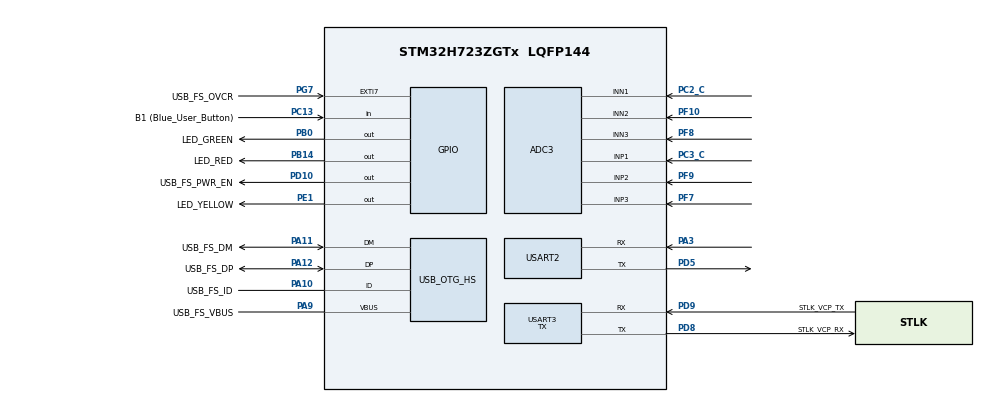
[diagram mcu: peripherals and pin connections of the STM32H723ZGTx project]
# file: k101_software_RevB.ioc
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ADC3.Channel-0\#ChannelRegularConversion=ADC_CHANNEL_1
ADC3.Channel-1\#ChannelRegularConversion=ADC_CHANNEL_2
ADC3.Channel-2\#ChannelRegularConversion=ADC_CHANNEL_3
ADC3.ClockPrescalerADC3=ADC_CLOCK_ASYNC_DIV4
ADC3.ContinuousConvMode=ENABLE
ADC3.ConversionDataManagement=ADC_CONVERSIONDATA_DMA_CIRCULAR
ADC3.DMAContinuousRequests=ENABLE
ADC3.NbrOfConversion=3
ADC3.NbrOfConversionFlag=1
ADC3.OffsetNumber-0\#ChannelRegularConversion=ADC_OFFSET_NONE
ADC3.OffsetNumber-1\#ChannelRegularConversion=ADC_OFFSET_NONE
ADC3.OffsetNumber-2\#ChannelRegularConversion=ADC_OFFSET_NONE
ADC3.OffsetSign-0\#ChannelRegularConversion=ADC3_OFFSET_SIGN_NEGATIVE
ADC3.OffsetSign-1\#ChannelRegularConversion=ADC3_OFFSET_SIGN_NEGATIVE
ADC3.OffsetSign-2\#ChannelRegularConversion=ADC3_OFFSET_SIGN_NEGATIVE
ADC3.Rank-0\#ChannelRegularConversion=1
ADC3.Rank-1\#ChannelRegularConversion=2
ADC3.Rank-2\#ChannelRegularConversion=3
ADC3.SamplingTime-0\#ChannelRegularConversion=ADC3_SAMPLETIME_12CYCLES_5
ADC3.SamplingTime-1\#ChannelRegularConversion=ADC3_SAMPLETIME_12CYCLES_5
ADC3.SamplingTime-2\#ChannelRegularConversion=ADC3_SAMPLETIME_12CYCLES_5
ADC3.SingleDiff-0\#ChannelRegularConversion=ADC_DIFFERENTIAL_ENDED
ADC3.SingleDiff-1\#ChannelRegularConversion=ADC_DIFFERENTIAL_ENDED
ADC3.SingleDiff-2\#ChannelRegularConversion=ADC_DIFFERENTIAL_ENDED
Dma.ADC3.0.Direction=DMA_PERIPH_TO_MEMORY
Dma.ADC3.0.EventEnable=DISABLE
Dma.ADC3.0.FIFOMode=DMA_FIFOMODE_DISABLE
Dma.ADC3.0.Instance=DMA1_Stream1
Dma.ADC3.0.MemDataAlignment=DMA_MDATAALIGN_HALFWORD
Dma.ADC3.0.MemInc=DMA_MINC_ENABLE
Dma.ADC3.0.Mode=DMA_CIRCULAR
Dma.ADC3.0.PeriphDataAlignment=DMA_PDATAALIGN_HALFWORD
Dma.ADC3.0.PeriphInc=DMA_PINC_DISABLE
Dma.ADC3.0.Polarity=HAL_DMAMUX_REQ_GEN_RISING
Dma.ADC3.0.Priority=DMA_PRIORITY_LOW
Dma.ADC3.0.RequestNumber=1
Dma.ADC3.0.SignalID=NONE
Dma.ADC3.0.SyncEnable=DISABLE
Dma.ADC3.0.SyncPolarity=HAL_DMAMUX_SYNC_NO_EVENT
Dma.ADC3.0.SyncRequestNumber=1
Dma.ADC3.0.SyncSignalID=NONE
Dma.Request0=ADC3
Dma.Request1=USART3_TX
Dma.Request2=USART2_TX
Dma.USART2_TX.2.Direction=DMA_MEMORY_TO_PERIPH
Dma.USART2_TX.2.EventEnable=DISABLE
Dma.USART2_TX.2.FIFOMode=DMA_FIFOMODE_DISABLE
Dma.USART2_TX.2.Instance=DMA1_Stream2
Dma.USART2_TX.2.MemDataAlignment=DMA_MDATAALIGN_BYTE
Dma.USART2_TX.2.MemInc=DMA_MINC_ENABLE
Dma.USART2_TX.2.Mode=DMA_NORMAL
Dma.USART2_TX.2.PeriphDataAlignment=DMA_PDATAALIGN_BYTE
Dma.USART2_TX.2.PeriphInc=DMA_PINC_DISABLE
Dma.USART2_TX.2.Polarity=HAL_DMAMUX_REQ_GEN_RISING
Dma.USART2_TX.2.Priority=DMA_PRIORITY_LOW
Dma.USART2_TX.2.RequestNumber=1
Dma.USART2_TX.2.SignalID=NONE
Dma.USART2_TX.2.SyncEnable=DISABLE
Dma.USART2_TX.2.SyncPolarity=HAL_DMAMUX_SYNC_NO_EVENT
Dma.USART2_TX.2.SyncRequestNumber=1
Dma.USART2_TX.2.SyncSignalID=NONE
Dma.USART3_TX.1.Direction=DMA_MEMORY_TO_PERIPH
Dma.USART3_TX.1.EventEnable=DISABLE
Dma.USART3_TX.1.FIFOMode=DMA_FIFOMODE_DISABLE
Dma.USART3_TX.1.Instance=DMA1_Stream0
Dma.USART3_TX.1.MemDataAlignment=DMA_MDATAALIGN_BYTE
Dma.USART3_TX.1.MemInc=DMA_MINC_ENABLE
Dma.USART3_TX.1.Mode=DMA_CIRCULAR
Dma.USART3_TX.1.PeriphDataAlignment=DMA_PDATAALIGN_BYTE
Dma.USART3_TX.1.PeriphInc=DMA_PINC_DISABLE
Dma.USART3_TX.1.Polarity=HAL_DMAMUX_REQ_GEN_RISING
Dma.USART3_TX.1.Priority=DMA_PRIORITY_LOW
Dma.USART3_TX.1.RequestNumber=1
Dma.USART3_TX.1.SignalID=NONE
Dma.USART3_TX.1.SyncEnable=DISABLE
Dma.USART3_TX.1.SyncPolarity=HAL_DMAMUX_SYNC_NO_EVENT
Dma.USART3_TX.1.SyncRequestNumber=1
Dma.USART3_TX.1.SyncSignalID=NONE
Mcu.Family=STM32H7
Mcu.Name=STM32H723ZGTx
Mcu.Package=LQFP144
NVIC.DMA1_Stream0_IRQn=true\:0\:0\:false\:false\:true\:false\:true\:true
NVIC.DMA1_Stream1_IRQn=true\:0\:0\:false\:false\:true\:false\:true\:true
NVIC.DMA1_Stream2_IRQn=true\:0\:0\:false\:false\:true\:false\:true\:true
NVIC.PriorityGroup=NVIC_PRIORITYGROUP_4
PA1.GPIO_Label=RMII_REF_CLK
PA1.Signal=ETH_REF_CLK
PA10.GPIO_Label=USB_FS_ID
PA10.Mode=OTG/Dual-Role-Device-FS
PA10.Signal=USB_OTG_HS_ID
PA11.GPIO_Label=USB_FS_DM
PA11.Mode=OTG/Dual-Role-Device-FS
PA11.Signal=USB_OTG_HS_DM
PA12.GPIO_Label=USB_FS_DP
PA12.Mode=OTG/Dual-Role-Device-FS
PA12.Signal=USB_OTG_HS_DP
PA13(JTMS/SWDIO).GPIO_Label=SWDIO
PA13(JTMS/SWDIO).Mode=Trace_Asynchronous_SW
PA13(JTMS/SWDIO).Signal=DEBUG_JTMS-SWDIO
PA14(JTCK/SWCLK).GPIO_Label=SWCLK
PA14(JTCK/SWCLK).Mode=Trace_Asynchronous_SW
PA14(JTCK/SWCLK).Signal=DEBUG_JTCK-SWCLK
PA2.GPIO_Label=RMII_MDIO
PA2.Signal=ETH_MDIO
PA3.Mode=Asynchronous
PA3.Signal=USART2_RX
PA7.GPIO_Label=RMII_CRS_DV
PA7.Signal=ETH_CRS_DV
PA9.GPIO_Label=USB_FS_VBUS
PA9.Mode=Activate_VBUS_FS
PA9.Signal=USB_OTG_HS_VBUS
PB0.GPIO_Label=LED_GREEN
PB0.Signal=GPIO_Output
PB13.GPIO_Label=RMII_TXD1
PB13.Signal=ETH_TXD1
PB14.GPIO_Label=LED_RED
PB14.Signal=GPIO_Output
PB3(JTDO/TRACESWO).GPIO_Label=SWO
PB3(JTDO/TRACESWO).Mode=Trace_Asynchronous_SW
PB3(JTDO/TRACESWO).Signal=DEBUG_JTDO-SWO
PC13.GPIO_Label=B1 (Blue_User_Button)
PC13.Signal=GPIO_Input
PC14-OSC32_IN.Mode=LSE-External-Oscillator
PC14-OSC32_IN.Signal=RCC_OSC32_IN
PC15-OSC32_OUT.Mode=LSE-External-Oscillator
PC15-OSC32_OUT.Signal=RCC_OSC32_OUT
PC2_C.Mode=IN1-Differential
PC2_C.Signal=ADC3_INN1
PC3_C.Mode=IN1-Differential
PC3_C.Signal=ADC3_INP1
PC4.GPIO_Label=RMII_RXD0
PC4.Signal=ETH_RXD0
PC5.GPIO_Label=RMII_RXD1
PC5.Signal=ETH_RXD1
PD10.GPIO_Label=USB_FS_PWR_EN
PD10.Signal=GPIO_Output
PD5.Mode=Asynchronous
PD5.Signal=USART2_TX
PD8.GPIO_Label=STLK_VCP_RX
PD8.Mode=Asynchronous
PD8.Signal=USART3_TX
PD9.GPIO_Label=STLK_VCP_TX
PD9.Mode=Asynchronous
PD9.Signal=USART3_RX
PE1.GPIO_Label=LED_YELLOW
PE1.Signal=GPIO_Output
PF10.Mode=IN2-Differential
PF10.Signal=ADC3_INN2
PF7.Mode=IN3-Differential
PF7.Signal=ADC3_INP3
PF8.Mode=IN3-Differential
PF8.Signal=ADC3_INN3
PF9.Mode=IN2-Differential
PF9.Signal=ADC3_INP2
PG11.GPIO_Label=RMII_TX_EN
PG11.Signal=ETH_TX_EN
PG13.GPIO_Label=RMII_TXD0
PG13.Signal=ETH_TXD0
PG7.GPIO_Label=USB_FS_OVCR
PG7.Signal=GPXTI7
PH0-OSC_IN.GPIO_Label=MCO
PH0-OSC_IN.Mode=HSE-External-Oscillator
PH0-OSC_IN.Signal=RCC_OSC_IN
PH1-OSC_OUT.Mode=HSE-External-Oscillator
PH1-OSC_OUT.Signal=RCC_OSC_OUT
ProjectManager.HeapSize=0x200
ProjectManager.StackSize=0x400
ProjectManager.TargetToolchain=STM32CubeIDE
RCC.ADCFreq_Value=96000000
RCC.APB1Freq_Value=137500000
RCC.APB2Freq_Value=137500000
RCC.APB3Freq_Value=137500000
RCC.APB4Freq_Value=137500000
RCC.CortexFreq_Value=550000000
RCC.D1PPRE=RCC_APB3_DIV2
RCC.D2PPRE1=RCC_APB1_DIV2
RCC.D2PPRE2=RCC_APB2_DIV2
RCC.D3PPRE=RCC_APB4_DIV2
RCC.DIVM1=4
RCC.DIVM2=1
RCC.DIVN1=275
RCC.DIVN2=24
RCC.DIVP1=1
RCC.DIVQ1=4
RCC.HCLKFreq_Value=275000000
RCC.HPRE=RCC_HCLK_DIV2
RCC.HSE_VALUE=8000000
RCC.PLLFRACN=0
RCC.PLLSourceVirtual=RCC_PLLSOURCE_HSE
RCC.SYSCLKFreq_VALUE=550000000
RCC.SYSCLKSource=RCC_SYSCLKSOURCE_PLLCLK
RCC.USBCLockSelection=RCC_USBCLKSOURCE_HSI48
RCC.USBFreq_Value=48000000
USART2.VirtualMode-Asynchronous=VM_ASYNC
USART3.DMADisableonRxErrorParam=ADVFEATURE_DMA_ENABLEONRXERROR
USART3.Mode=MODE_TX
USART3.VirtualMode-Asynchronous=VM_ASYNC
VP_MEMORYMAP_VS_MEMORYMAP.Mode=CurAppReg
board=NUCLEO-H723ZG

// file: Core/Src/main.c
/* USER CODE BEGIN Header */
/**
  ******************************************************************************
  * @file           : main.c
  * @brief          : Main program body
  ******************************************************************************
  * @attention
  *
  * Copyright (c) 2024 STMicroelectronics.
  * All rights reserved.
  *
  * This software is licensed under terms that can be found in the LICENSE file
  * in the root directory of this software component.
  * If no LICENSE file comes with this software, it is provided AS-IS.
  *
  ******************************************************************************
  */
/* USER CODE END Header */
#include "main.h"

/* USER CODE BEGIN Includes */
#include "string.h"
#include <stdio.h>
/* USER CODE END Includes */

ADC_HandleTypeDef hadc3;
DMA_HandleTypeDef hdma_adc3;

UART_HandleTypeDef huart2;
UART_HandleTypeDef huart3;
DMA_HandleTypeDef hdma_usart3_tx;

/* USER CODE BEGIN PV */
int m, b;
/* USER CODE END PV */

void SystemClock_Config(void);
static void MX_GPIO_Init(void);
static void MX_DMA_Init(void);
static void MX_USART3_UART_Init(void);
static void MX_USB_OTG_HS_USB_Init(void);
static void MX_ADC3_Init(void);
static void MX_USART2_UART_Init(void);
/* USER CODE BEGIN PFP */
HAL_StatusTypeDef ret;
/* USER CODE END PFP */

int main(void)
{

  /* USER CODE BEGIN 1 */
	uint16_t pt_data[3] = {0};
  /* USER CODE END 1 */

  /* MCU Configuration--------------------------------------------------------*/

  /* Reset of all peripherals, Initializes the Flash interface and the Systick. */
  HAL_Init();

  /* Configure the system clock */
  SystemClock_Config();

  /* Initialize all configured peripherals */
  MX_GPIO_Init();
  MX_DMA_Init();
  MX_USART3_UART_Init();
  MX_USB_OTG_HS_USB_Init();
  MX_ADC3_Init();
  MX_USART2_UART_Init();
  /* USER CODE BEGIN 2 */
  char str[16] = {"{    ,    ,    }"};

HAL_UART_Transmit_DMA(&huart3, (unsigned char*)&str, 16);
//HAL_UART_Transmit_DMA(&huart2, (unsigned char*)&str, 16);

  //pretty good impreovement in precision

  ret = HAL_ADCEx_Calibration_Start(&hadc3, ADC_CALIB_OFFSET, ADC_DIFFERENTIAL_ENDED) ;
   if(ret != HAL_OK)
   	{
   		Error_Handler();
   	}

   	// Small delay to ensur end of calibration procedure
   	HAL_Delay(10);

  HAL_ADC_Start_DMA(&hadc3, (uint32_t *)pt_data, 3);

  /* USER CODE END 2 */

  /* Infinite loop */
  while (1)
  {

    /* USER CODE BEGIN 3 */

		  sprintf(&str, "{%4d,%4d,%4d}", pt_data[0], pt_data[1], pt_data[2]);
		  //HAL_Delay(200);
  }
  /* USER CODE END 3 */
}

void SystemClock_Config(void)
{
  RCC_OscInitTypeDef RCC_OscInitStruct = {0};
  RCC_ClkInitTypeDef RCC_ClkInitStruct = {0};

  /** Supply configuration update enable
  */
  HAL_PWREx_ConfigSupply(PWR_LDO_SUPPLY);

  /** Configure the main internal regulator output voltage
  */
  __HAL_PWR_VOLTAGESCALING_CONFIG(PWR_REGULATOR_VOLTAGE_SCALE0);

  while(!__HAL_PWR_GET_FLAG(PWR_FLAG_VOSRDY)) {}

  /** Initializes the RCC Oscillators according to the specified parameters
  * in the RCC_OscInitTypeDef structure.
  */
  RCC_OscInitStruct.OscillatorType = RCC_OSCILLATORTYPE_HSI48|RCC_OSCILLATORTYPE_HSE;
  RCC_OscInitStruct.HSEState = RCC_HSE_ON;
  RCC_OscInitStruct.HSI48State = RCC_HSI48_ON;
  RCC_OscInitStruct.PLL.PLLState = RCC_PLL_ON;
  RCC_OscInitStruct.PLL.PLLSource = RCC_PLLSOURCE_HSE;
  RCC_OscInitStruct.PLL.PLLM = 4;
  RCC_OscInitStruct.PLL.PLLN = 275;
  RCC_OscInitStruct.PLL.PLLP = 1;
  RCC_OscInitStruct.PLL.PLLQ = 4;
  RCC_OscInitStruct.PLL.PLLR = 2;
  RCC_OscInitStruct.PLL.PLLRGE = RCC_PLL1VCIRANGE_1;
  RCC_OscInitStruct.PLL.PLLVCOSEL = RCC_PLL1VCOWIDE;
  RCC_OscInitStruct.PLL.PLLFRACN = 0;
  if (HAL_RCC_OscConfig(&RCC_OscInitStruct) != HAL_OK)
  {
    Error_Handler();
  }

  /** Initializes the CPU, AHB and APB buses clocks
  */
  RCC_ClkInitStruct.ClockType = RCC_CLOCKTYPE_HCLK|RCC_CLOCKTYPE_SYSCLK
                              |RCC_CLOCKTYPE_PCLK1|RCC_CLOCKTYPE_PCLK2
                              |RCC_CLOCKTYPE_D3PCLK1|RCC_CLOCKTYPE_D1PCLK1;
  RCC_ClkInitStruct.SYSCLKSource = RCC_SYSCLKSOURCE_PLLCLK;
  RCC_ClkInitStruct.SYSCLKDivider = RCC_SYSCLK_DIV1;
  RCC_ClkInitStruct.AHBCLKDivider = RCC_HCLK_DIV2;
  RCC_ClkInitStruct.APB3CLKDivider = RCC_APB3_DIV2;
  RCC_ClkInitStruct.APB1CLKDivider = RCC_APB1_DIV2;
  RCC_ClkInitStruct.APB2CLKDivider = RCC_APB2_DIV2;
  RCC_ClkInitStruct.APB4CLKDivider = RCC_APB4_DIV2;

  if (HAL_RCC_ClockConfig(&RCC_ClkInitStruct, FLASH_LATENCY_3) != HAL_OK)
  {
    Error_Handler();
  }
}

static void MX_ADC3_Init(void)
{

  ADC_ChannelConfTypeDef sConfig = {0};

  /** Common config
  */
  hadc3.Instance = ADC3;
  hadc3.Init.ClockPrescaler = ADC_CLOCK_ASYNC_DIV4;
  hadc3.Init.Resolution = ADC_RESOLUTION_12B;
  hadc3.Init.DataAlign = ADC3_DATAALIGN_RIGHT;
  hadc3.Init.ScanConvMode = ADC_SCAN_ENABLE;
  hadc3.Init.EOCSelection = ADC_EOC_SINGLE_CONV;
  hadc3.Init.LowPowerAutoWait = ENABLE;
  hadc3.Init.ContinuousConvMode = ENABLE;
  hadc3.Init.NbrOfConversion = 3;
  hadc3.Init.DiscontinuousConvMode = DISABLE;
  hadc3.Init.ExternalTrigConv = ADC_SOFTWARE_START;
  hadc3.Init.ExternalTrigConvEdge = ADC_EXTERNALTRIGCONVEDGE_NONE;
  hadc3.Init.DMAContinuousRequests = ENABLE;
  hadc3.Init.SamplingMode = ADC_SAMPLING_MODE_NORMAL;
  hadc3.Init.ConversionDataManagement = ADC_CONVERSIONDATA_DMA_CIRCULAR;
  hadc3.Init.Overrun = ADC_OVR_DATA_PRESERVED;
  hadc3.Init.LeftBitShift = ADC_LEFTBITSHIFT_NONE;
  hadc3.Init.OversamplingMode = DISABLE;
  hadc3.Init.Oversampling.Ratio = ADC3_OVERSAMPLING_RATIO_2;
  if (HAL_ADC_Init(&hadc3) != HAL_OK)
  {
    Error_Handler();
  }

  /** Configure Regular Channel
  */
  sConfig.Channel = ADC_CHANNEL_1;
  sConfig.Rank = ADC_REGULAR_RANK_1;
  sConfig.SamplingTime = ADC3_SAMPLETIME_12CYCLES_5;
  sConfig.SingleDiff = ADC_DIFFERENTIAL_ENDED;
  sConfig.OffsetNumber = ADC_OFFSET_NONE;
  sConfig.Offset = 0;
  sConfig.OffsetSign = ADC3_OFFSET_SIGN_NEGATIVE;
  if (HAL_ADC_ConfigChannel(&hadc3, &sConfig) != HAL_OK)
  {
    Error_Handler();
  }

  /** Configure Regular Channel
  */
  sConfig.Channel = ADC_CHANNEL_2;
  sConfig.Rank = ADC_REGULAR_RANK_2;
  if (HAL_ADC_ConfigChannel(&hadc3, &sConfig) != HAL_OK)
  {
    Error_Handler();
  }

  /** Configure Regular Channel
  */
  sConfig.Channel = ADC_CHANNEL_3;
  sConfig.Rank = ADC_REGULAR_RANK_3;
  if (HAL_ADC_ConfigChannel(&hadc3, &sConfig) != HAL_OK)
  {
    Error_Handler();
  }

}

static void MX_USART2_UART_Init(void)
{

  huart2.Instance = USART2;
  huart2.Init.BaudRate = 9600;
  huart2.Init.WordLength = UART_WORDLENGTH_8B;
  huart2.Init.StopBits = UART_STOPBITS_1;
  huart2.Init.Parity = UART_PARITY_NONE;
  huart2.Init.Mode = UART_MODE_TX;
  huart2.Init.HwFlowCtl = UART_HWCONTROL_NONE;
  huart2.Init.OverSampling = UART_OVERSAMPLING_16;
  huart2.Init.OneBitSampling = UART_ONE_BIT_SAMPLE_DISABLE;
  huart2.Init.ClockPrescaler = UART_PRESCALER_DIV1;
  huart2.AdvancedInit.AdvFeatureInit = UART_ADVFEATURE_NO_INIT;
  if (HAL_UART_Init(&huart2) != HAL_OK)
  {
    Error_Handler();
  }
  if (HAL_UARTEx_SetTxFifoThreshold(&huart2, UART_TXFIFO_THRESHOLD_1_8) != HAL_OK)
  {
    Error_Handler();
  }
  if (HAL_UARTEx_SetRxFifoThreshold(&huart2, UART_RXFIFO_THRESHOLD_1_8) != HAL_OK)
  {
    Error_Handler();
  }
  if (HAL_UARTEx_DisableFifoMode(&huart2) != HAL_OK)
  {
    Error_Handler();
  }

}

static void MX_USART3_UART_Init(void)
{

  huart3.Instance = USART3;
  huart3.Init.BaudRate = 115200;
  huart3.Init.WordLength = UART_WORDLENGTH_8B;
  huart3.Init.StopBits = UART_STOPBITS_1;
  huart3.Init.Parity = UART_PARITY_NONE;
  huart3.Init.Mode = UART_MODE_TX;
  huart3.Init.HwFlowCtl = UART_HWCONTROL_NONE;
  huart3.Init.OverSampling = UART_OVERSAMPLING_16;
  huart3.Init.OneBitSampling = UART_ONE_BIT_SAMPLE_DISABLE;
  huart3.Init.ClockPrescaler = UART_PRESCALER_DIV1;
  huart3.AdvancedInit.AdvFeatureInit = UART_ADVFEATURE_NO_INIT;
  if (HAL_UART_Init(&huart3) != HAL_OK)
  {
    Error_Handler();
  }
  if (HAL_UARTEx_SetTxFifoThreshold(&huart3, UART_TXFIFO_THRESHOLD_1_8) != HAL_OK)
  {
    Error_Handler();
  }
  if (HAL_UARTEx_SetRxFifoThreshold(&huart3, UART_RXFIFO_THRESHOLD_1_8) != HAL_OK)
  {
    Error_Handler();
  }
  if (HAL_UARTEx_DisableFifoMode(&huart3) != HAL_OK)
  {
    Error_Handler();
  }

}

static void MX_USB_OTG_HS_USB_Init(void)
{

}

static void MX_DMA_Init(void)
{

  /* DMA controller clock enable */
  __HAL_RCC_DMA1_CLK_ENABLE();

  /* DMA interrupt init */
  /* DMA1_Stream0_IRQn interrupt configuration */
  HAL_NVIC_SetPriority(DMA1_Stream0_IRQn, 0, 0);
  HAL_NVIC_EnableIRQ(DMA1_Stream0_IRQn);
  /* DMA1_Stream1_IRQn interrupt configuration */
  HAL_NVIC_SetPriority(DMA1_Stream1_IRQn, 0, 0);
  HAL_NVIC_EnableIRQ(DMA1_Stream1_IRQn);

}

static void MX_GPIO_Init(void)
{
  GPIO_InitTypeDef GPIO_InitStruct = {0};

  /* GPIO Ports Clock Enable */
  __HAL_RCC_GPIOC_CLK_ENABLE();
  __HAL_RCC_GPIOF_CLK_ENABLE();
  __HAL_RCC_GPIOH_CLK_ENABLE();
  __HAL_RCC_GPIOA_CLK_ENABLE();
  __HAL_RCC_GPIOB_CLK_ENABLE();
  __HAL_RCC_GPIOD_CLK_ENABLE();
  __HAL_RCC_GPIOG_CLK_ENABLE();
  __HAL_RCC_GPIOE_CLK_ENABLE();

  /*Configure GPIO pin Output Level */
  HAL_GPIO_WritePin(GPIOB, LED_GREEN_Pin|LED_RED_Pin, GPIO_PIN_RESET);

  /*Configure GPIO pin Output Level */
  HAL_GPIO_WritePin(USB_FS_PWR_EN_GPIO_Port, USB_FS_PWR_EN_Pin, GPIO_PIN_RESET);

  /*Configure GPIO pin Output Level */
  HAL_GPIO_WritePin(LED_YELLOW_GPIO_Port, LED_YELLOW_Pin, GPIO_PIN_RESET);

  /*Configure GPIO pin : B1_Pin */
  GPIO_InitStruct.Pin = B1_Pin;
  GPIO_InitStruct.Mode = GPIO_MODE_INPUT;
  GPIO_InitStruct.Pull = GPIO_NOPULL;
  HAL_GPIO_Init(B1_GPIO_Port, &GPIO_InitStruct);

  /*Configure GPIO pins : RMII_REF_CLK_Pin RMII_MDIO_Pin RMII_CRS_DV_Pin */
  GPIO_InitStruct.Pin = RMII_REF_CLK_Pin|RMII_MDIO_Pin|RMII_CRS_DV_Pin;
  GPIO_InitStruct.Mode = GPIO_MODE_AF_PP;
  GPIO_InitStruct.Pull = GPIO_NOPULL;
  GPIO_InitStruct.Speed = GPIO_SPEED_FREQ_LOW;
  GPIO_InitStruct.Alternate = GPIO_AF11_ETH;
  HAL_GPIO_Init(GPIOA, &GPIO_InitStruct);

  /*Configure GPIO pins : RMII_RXD0_Pin RMII_RXD1_Pin */
  GPIO_InitStruct.Pin = RMII_RXD0_Pin|RMII_RXD1_Pin;
  GPIO_InitStruct.Mode = GPIO_MODE_AF_PP;
  GPIO_InitStruct.Pull = GPIO_NOPULL;
  GPIO_InitStruct.Speed = GPIO_SPEED_FREQ_LOW;
  GPIO_InitStruct.Alternate = GPIO_AF11_ETH;
  HAL_GPIO_Init(GPIOC, &GPIO_InitStruct);

  /*Configure GPIO pins : LED_GREEN_Pin LED_RED_Pin */
  GPIO_InitStruct.Pin = LED_GREEN_Pin|LED_RED_Pin;
  GPIO_InitStruct.Mode = GPIO_MODE_OUTPUT_PP;
  GPIO_InitStruct.Pull = GPIO_NOPULL;
  GPIO_InitStruct.Speed = GPIO_SPEED_FREQ_LOW;
  HAL_GPIO_Init(GPIOB, &GPIO_InitStruct);

  /*Configure GPIO pin : RMII_TXD1_Pin */
  GPIO_InitStruct.Pin = RMII_TXD1_Pin;
  GPIO_InitStruct.Mode = GPIO_MODE_AF_PP;
  GPIO_InitStruct.Pull = GPIO_NOPULL;
  GPIO_InitStruct.Speed = GPIO_SPEED_FREQ_LOW;
  GPIO_InitStruct.Alternate = GPIO_AF11_ETH;
  HAL_GPIO_Init(RMII_TXD1_GPIO_Port, &GPIO_InitStruct);

  /*Configure GPIO pin : USB_FS_PWR_EN_Pin */
  GPIO_InitStruct.Pin = USB_FS_PWR_EN_Pin;
  GPIO_InitStruct.Mode = GPIO_MODE_OUTPUT_PP;
  GPIO_InitStruct.Pull = GPIO_NOPULL;
  GPIO_InitStruct.Speed = GPIO_SPEED_FREQ_LOW;
  HAL_GPIO_Init(USB_FS_PWR_EN_GPIO_Port, &GPIO_InitStruct);

  /*Configure GPIO pin : USB_FS_OVCR_Pin */
  GPIO_InitStruct.Pin = USB_FS_OVCR_Pin;
  GPIO_InitStruct.Mode = GPIO_MODE_IT_RISING;
  GPIO_InitStruct.Pull = GPIO_NOPULL;
  HAL_GPIO_Init(USB_FS_OVCR_GPIO_Port, &GPIO_InitStruct);

  /*Configure GPIO pin : USB_FS_VBUS_Pin */
  GPIO_InitStruct.Pin = USB_FS_VBUS_Pin;
  GPIO_InitStruct.Mode = GPIO_MODE_INPUT;
  GPIO_InitStruct.Pull = GPIO_NOPULL;
  HAL_GPIO_Init(USB_FS_VBUS_GPIO_Port, &GPIO_InitStruct);

  /*Configure GPIO pin : USB_FS_ID_Pin */
  GPIO_InitStruct.Pin = USB_FS_ID_Pin;
  GPIO_InitStruct.Mode = GPIO_MODE_AF_PP;
  GPIO_InitStruct.Pull = GPIO_NOPULL;
  GPIO_InitStruct.Speed = GPIO_SPEED_FREQ_LOW;
  GPIO_InitStruct.Alternate = GPIO_AF10_OTG1_HS;
  HAL_GPIO_Init(USB_FS_ID_GPIO_Port, &GPIO_InitStruct);

  /*Configure GPIO pins : RMII_TX_EN_Pin RMII_TXD0_Pin */
  GPIO_InitStruct.Pin = RMII_TX_EN_Pin|RMII_TXD0_Pin;
  GPIO_InitStruct.Mode = GPIO_MODE_AF_PP;
  GPIO_InitStruct.Pull = GPIO_NOPULL;
  GPIO_InitStruct.Speed = GPIO_SPEED_FREQ_LOW;
  GPIO_InitStruct.Alternate = GPIO_AF11_ETH;
  HAL_GPIO_Init(GPIOG, &GPIO_InitStruct);

  /*Configure GPIO pin : LED_YELLOW_Pin */
  GPIO_InitStruct.Pin = LED_YELLOW_Pin;
  GPIO_InitStruct.Mode = GPIO_MODE_OUTPUT_PP;
  GPIO_InitStruct.Pull = GPIO_NOPULL;
  GPIO_InitStruct.Speed = GPIO_SPEED_FREQ_LOW;
  HAL_GPIO_Init(LED_YELLOW_GPIO_Port, &GPIO_InitStruct);

}

void Error_Handler(void)
{
  __disable_irq();
  while (1)
  {
  }
}
